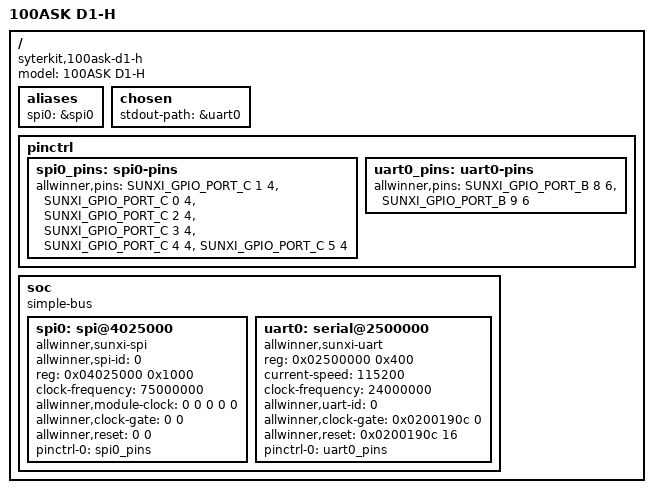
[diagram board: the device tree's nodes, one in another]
// SPDX-License-Identifier: GPL-2.0+
/dts-v1/;

#include <dt-bindings/gpio/sunxi-gpio.h>

/ {
	#address-cells = <1>;
	#size-cells = <1>;
	model = "100ASK D1-H";
	compatible = "syterkit,100ask-d1-h";

	aliases {
		spi0 = &spi0;
	};

	chosen {
		stdout-path = &uart0;
	};

	pinctrl {
		spi0_pins: spi0-pins {
			allwinner,pins =
				<SUNXI_GPIO_PORT_C 1 4>,
				<SUNXI_GPIO_PORT_C 0 4>,
				<SUNXI_GPIO_PORT_C 2 4>,
				<SUNXI_GPIO_PORT_C 3 4>,
				<SUNXI_GPIO_PORT_C 4 4>,
				<SUNXI_GPIO_PORT_C 5 4>;
		};

		uart0_pins: uart0-pins {
			allwinner,pins =
				<SUNXI_GPIO_PORT_B 8 6>,
				<SUNXI_GPIO_PORT_B 9 6>;
		};
	};

	soc {
		compatible = "simple-bus";
		#address-cells = <1>;
		#size-cells = <1>;
		ranges;

		spi0: spi@4025000 {
			compatible = "allwinner,sunxi-spi";
			allwinner,spi-id = <0>;
			reg = <0x04025000 0x1000>;
			clock-frequency = <75000000>;
			allwinner,module-clock = <0 0 0 0 0>;
			allwinner,clock-gate = <0 0>;
			allwinner,reset = <0 0>;
			pinctrl-names = "default";
			pinctrl-0 = <&spi0_pins>;
			status = "okay";
		};

		uart0: serial@2500000 {
			compatible = "allwinner,sunxi-uart";
			reg = <0x02500000 0x400>;
			current-speed = <115200>;
			clock-frequency = <24000000>;
			allwinner,uart-id = <0>;
			allwinner,clock-gate = <0x0200190c 0>;
			allwinner,reset = <0x0200190c 16>;
			pinctrl-names = "default";
			pinctrl-0 = <&uart0_pins>;
			status = "okay";
		};
	};
};
